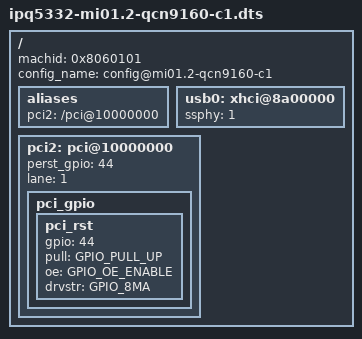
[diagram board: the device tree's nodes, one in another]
/*
 * Copyright (c) 2016-2019, The Linux Foundation. All rights reserved.
 *
 * Copyright (c) 2022 Qualcomm Innovation Center, Inc. All rights reserved.
 *
 * This program is free software; you can redistribute it and/or modify
 * it under the terms of the GNU General Public License version 2 and
 * only version 2 as published by the Free Software Foundation.
 *
 * This program is distributed in the hope that it will be useful,
 * but WITHOUT ANY WARRANTY; without even the implied warranty of
 * MERCHANTABILITY or FITNESS FOR A PARTICULAR PURPOSE.  See the
 * GNU General Public License for more details.
 */

/dts-v1/;
#include "ipq5332-mi01.2.dts"
/ {
	machid = <0x8060101>;
	config_name = "config@mi01.2-qcn9160-c1";

	aliases {
		/delete-property/pci0;
		pci2 = "/pci@10000000";
	};

	usb0: xhci@8a00000 {
		ssphy = <1>;
	};

	pci2: pci@10000000 {
		status = "ok";
		perst_gpio = <44>;
		lane = <1>;
		pci_gpio {
			pci_rst {
				gpio = <44>;
				pull = <GPIO_PULL_UP>;
				oe = <GPIO_OE_ENABLE>;
				drvstr = <GPIO_8MA>;
			};
		};
	};
};
